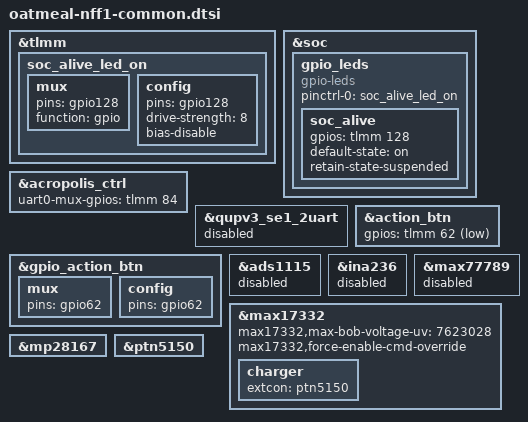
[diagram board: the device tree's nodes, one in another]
// SPDX-License-Identifier: GPL-2.0

#include "oatmeal.dtsi"

&tlmm {
	soc_alive_led_on: soc_alive_led_on {
		mux {
			pins = "gpio128";
			function = "gpio";
		};

		config {
			pins = "gpio128";
			drive-strength = <8>;
			bias-disable;
		};
	};
};

&soc {
	gpio_leds {
		compatible = "gpio-leds";
		pinctrl-names = "default";
		pinctrl-0 = <&soc_alive_led_on>;

		soc_alive {
			gpios = <&tlmm 128 GPIO_ACTIVE_HIGH>;
			default-state = "on";
			retain-state-suspended;
		};
	};
};

&acropolis_ctrl {
	uart0-mux-gpios = <&tlmm 84 GPIO_ACTIVE_HIGH>;
};

&qupv3_se1_2uart {
	status = "disabled";
};

&gpio_action_btn {
	mux {
		pins = "gpio62";
	};

	config {
		pins = "gpio62";
	};
};

&action_btn {
	gpios = <&tlmm 62 GPIO_ACTIVE_LOW>;
};

&ads1115 {
	status = "disabled";
};

&ina236 {
	status = "disabled";
};

&max77789 {
	status = "disabled";
};

&max17332 {
	max17332,max-bob-voltage-uv = <7623028>;
	max17332,force-enable-cmd-override;
	/delete-property/ max17332,reset-vsys-on-usb-insertion;

	charger {
		extcon = <&ptn5150>;
	};
};

&mp28167 {
	status = "ok";
};

&ptn5150 {
	status = "ok";
};
